# STM32F101_iown register map
Vendor: iown-homecontrol; Series: CM3; File version: 1.3
CPU: CM3 r1p1, little endian, no MPU, no FPU, VTOR, 4 interrupt priority bits
Registers are 32-bit, read-write, reset 0x0 unless marked. A register's access mark holds for its fields unless they carry their own. Offsets are from the block's base; [hi:lo] are bit positions.

## RTC — Real time clock
Base 0x40002800
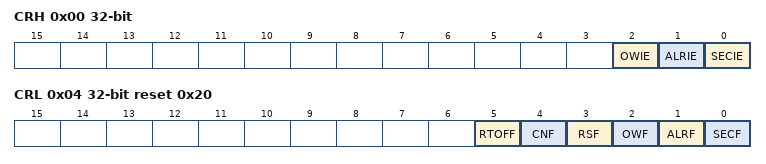
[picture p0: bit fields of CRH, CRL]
0x00 CRH — RTC Control Register High
  [2] OWIE — Overflow interrupt Enable
    0=Disabled (Overflow interrupt is masked); 1=Enabled (Overflow interrupt is enabled)
  [1] ALRIE — Alarm interrupt Enable
    0=Disabled (Alarm interrupt is masked); 1=Enabled (Alarm interrupt is enabled)
  [0] SECIE — Second interrupt Enable
    0=Disabled (Second interrupt is masked); 1=Enabled (Second interrupt is enabled)
0x04 CRL reset 0x20 — RTC Control Register Low
  [5] RTOFF ro — RTC operation OFF
    on read: 0=Enabled (Last write operation on RTC registers is still ongoing); 1=Disabled (Last write operation on RTC registers terminated)
  [4] CNF — Configuration Flag
    0=Exit configuration mode (start update of RTC registers); 1=Enter configuration mode
  [3] RSF write-0-clears — Registers Synchronized Flag
    on read: 0=NotSynchronized (Registers not yet synchronized); 1=Synchronized (Registers synchronized) | on write: 0=Clear flag
  [2] OWF write-0-clears — Overflow Flag
    on read: 0=NoOverflow (Overflow not detected); 1=Overflow (32-bit programmable counter overflow occurred) | on write: 0=Clear flag
  [1] ALRF write-0-clears — Alarm Flag
    on read: 0=NoAlarm (Alarm not detected); 1=Alarm detected | on write: 0=Clear flag
  [0] SECF write-0-clears — Second Flag
    on read: 0=NoPrescalerOverflow (Second flag condition not met); 1=PrescalerOverflow (Second flag condition met) | on write: 0=Clear flag
0x08 PRLH wo — RTC Prescaler Load Register High
  [3:0] PRLH
0x0C PRLL wo reset 0x8000 — RTC Prescaler Load Register Low
  [15:0] PRLL — RTC Prescaler Divider Register Low
0x10 DIVH ro — RTC Prescaler Divider Register High
  [3:0] DIVH — RTC prescaler divider register high
0x14 DIVL ro reset 0x8000 — RTC Prescaler Divider Register Low
  [15:0] DIVL — RTC prescaler divider register Low
0x18 CNTH — RTC Counter Register High
  [15:0] CNTH — RTC counter register high
0x1C CNTL — RTC Counter Register Low
  [15:0] CNTL — RTC counter register Low
0x20 ALRH wo reset 0xFFFF — RTC Alarm Register High
  [15:0] ALRH — RTC alarm register high
0x24 ALRL wo reset 0xFFFF — RTC Alarm Register Low
  [15:0] ALRL — RTC alarm register low

## WWDG — Window watchdog
Base 0x40002C00
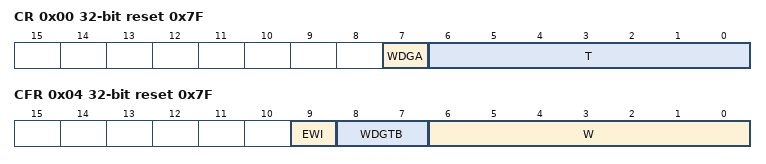
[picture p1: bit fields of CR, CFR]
0x00 CR reset 0x7F — Control register (WWDG_CR)
  [7] WDGA — Activation bit
    0=Disabled (Watchdog disabled); 1=Enabled (Watchdog enabled)
  [6:0] T — 7-bit counter (MSB to LSB)
0x04 CFR reset 0x7F — Configuration register (WWDG_CFR)
  [9] EWI — Early Wakeup Interrupt
    on write: 1=Enable (interrupt occurs whenever the counter reaches the value 0x40)
  [8:7] WDGTB — Timer Base
    0=Div1 (Counter clock (PCLK1 div 4096) div 1); 1=Div2 (Counter clock (PCLK1 div 4096) div 2); 2=Div4 (Counter clock (PCLK1 div 4096) div 4); 3=Div8 (Counter clock (PCLK1 div 4096) div 8)
  [6:0] W — 7-bit window value
0x08 SR — Status register (WWDG_SR)
  [0] EWIF write-0-clears — Early Wakeup Interrupt
    on read: 0=Finished (The EWI Interrupt Service Routine has been serviced); 1=Pending (The EWI Interrupt Service Routine has been triggered) | on write: 0=Finished (The EWI Interrupt Service Routine has been serviced)

## IWDG — Independent watchdog
Base 0x40003000
0x00 KR wo — Key register (IWDG_KR)
  [15:0] KEY — Key value
    on write: 0x5555=Enable access to PR, RLR and WINR registers (0x5555); 0xAAAA=Reset the watchdog value (0xAAAA); 0xCCCC=Start the watchdog (0xCCCC)
0x04 PR — Prescaler register (IWDG_PR)
  [2:0] PR — Prescaler divider
    0=DivideBy4 (Divider /4); 1=DivideBy8 (Divider /8); 2=DivideBy16 (Divider /16); 3=DivideBy32 (Divider /32); 4=DivideBy64 (Divider /64); 5=DivideBy128 (Divider /128); 6=DivideBy256 (Divider /256); 7=DivideBy256bis (Divider /256)
0x08 RLR reset 0xFFF — Reload register (IWDG_RLR)
  [11:0] RL — Watchdog counter reload value
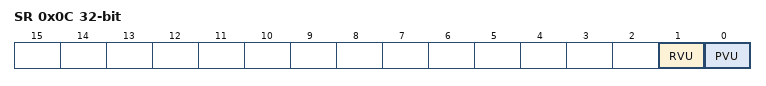
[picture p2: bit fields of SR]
0x0C SR ro — Status register (IWDG_SR)
  [1] RVU — Watchdog counter reload value update
  [0] PVU — Watchdog prescaler value update
